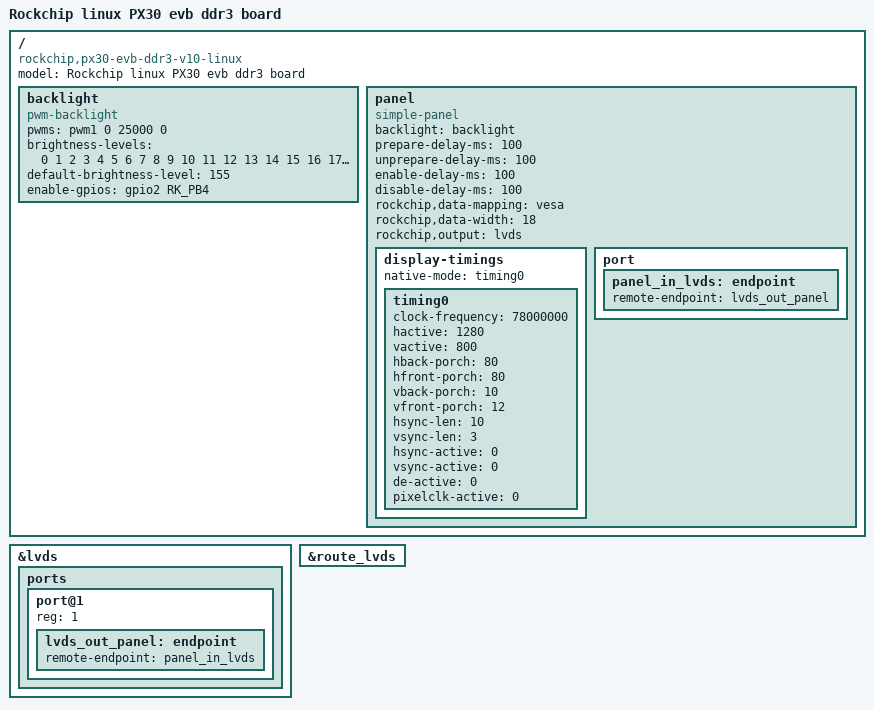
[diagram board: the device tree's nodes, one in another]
// SPDX-License-Identifier: (GPL-2.0+ OR MIT)
/*
 * Copyright (c) 2021 Fuzhou Rockchip Electronics Co., Ltd
 */


/ {
	model = "Rockchip linux PX30 evb ddr3 board";
	compatible = "rockchip,px30-evb-ddr3-v10-linux", "rockchip,px30";
	/delete-node/ test-power;

    backlight: backlight {
        compatible = "pwm-backlight";
        pwms = <&pwm1 0 25000 0>;
        brightness-levels = <
              0   1   2   3   4   5   6   7
              8   9  10  11  12  13  14  15
             16  17  18  19  20  21  22  23
             24  25  26  27  28  29  30  31
             32  33  34  35  36  37  38  39
             40  41  42  43  44  45  46  47
             48  49  50  51  52  53  54  55
             56  57  58  59  60  61  62  63
             64  65  66  67  68  69  70  71
             72  73  74  75  76  77  78  79
             80  81  82  83  84  85  86  87
             88  89  90  91  92  93  94  95
             96  97  98  99 100 101 102 103
            104 105 106 107 108 109 110 111
            112 113 114 115 116 117 118 119
            120 121 122 123 124 125 126 127
            128 129 130 131 132 133 134 135
            136 137 138 139 140 141 142 143
            144 145 146 147 148 149 150 151
            152 153 154 155 156 157 158 159
            160 161 162 163 164 165 166 167
            168 169 170 171 172 173 174 175
            176 177 178 179 180 181 182 183
            184 185 186 187 188 189 190 191
            192 193 194 195 196 197 198 199
            200 201 202 203 204 205 206 207
            208 209 210 211 212 213 214 215
            216 217 218 219 220 221 222 223
            224 225 226 227 228 229 230 231
            232 233 234 235 236 237 238 239
            240 241 242 243 244 245 246 247
            248 249 250 251 252 253 254 255>;
        default-brightness-level = <155>;
        enable-gpios = <&gpio2 RK_PB4 GPIO_ACTIVE_HIGH>;
    };

    panel {
		compatible ="simple-panel";
		backlight = <&backlight>;
		//enable-gpios = <&gpio0 RK_PC0 GPIO_ACTIVE_LOW>;
		//reset-gpios = <&gpio3 RK_PD1 GPIO_ACTIVE_LOW>;

		prepare-delay-ms = <100>;
		unprepare-delay-ms = <100>;
		enable-delay-ms = <100>;
		disable-delay-ms = <100>;
		rockchip,data-mapping  = "vesa";
		rockchip,data-width = <18>;
		rockchip,output = "lvds";
		status = "okay";

		display-timings {
			native-mode = <&timing0>;

           // //------------------LVDS RK101II01D-------------------------------
		    timing0: timing0 {
		    	clock-frequency = <78000000>;
		    	hactive = <1280>;
		    	vactive = <800>;
		    	hback-porch = <80>;
		    	hfront-porch = <80>;
		    	vback-porch = <10>;
		    	vfront-porch = <12>;
		    	hsync-len = <10>;
		    	vsync-len = <3>;
		    	hsync-active = <0>;
		    	vsync-active = <0>;
		    	de-active = <0>;
		    	pixelclk-active = <0>;
		    };
            //------------------LVDS RK101II01D-------------------------------
		};

		port {
			panel_in_lvds: endpoint {
				remote-endpoint = <&lvds_out_panel>;
			};
		};
    };
};

//LVDS
&lvds {
	status = "okay";
	ports {
		port@1 {
			reg = <1>;

			lvds_out_panel: endpoint {
				remote-endpoint = <&panel_in_lvds>;
			};
		};
	};
};

&route_lvds {
	status = "okay";
};

